# STM32L100C6U6 register map
File version: 1.0
Registers are 32-bit, access not given, reset 0x0 unless marked. A register's access mark holds for its fields unless they carry their own. Offsets are from the block's base; [hi:lo] are bit positions; {n}, {i} and the like mark numbered series.

## SYSCFG
Base 0x40010000
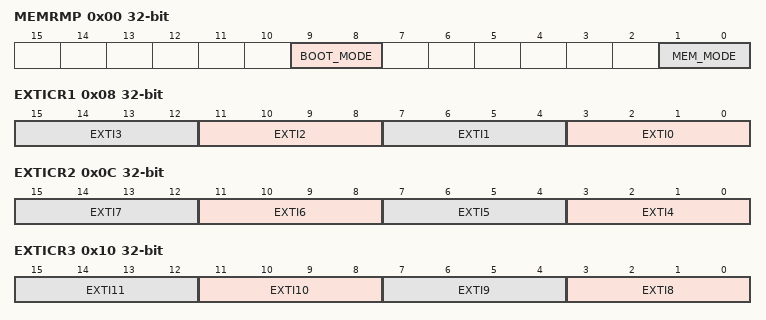
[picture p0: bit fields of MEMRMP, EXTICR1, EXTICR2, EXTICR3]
0x00 MEMRMP
  [9:8] BOOT_MODE, [1:0] MEM_MODE
0x04 PMC
  [0] USBPU
0x08 EXTICR1
  [4n+3:4n] EXTI{n} (n=0..3)
0x0C EXTICR2
  [4n-13:4n-16] EXTI{n} (n=4..7)
0x10 EXTICR3
  [4n-29:4n-32] EXTI{n} (n=8..11)
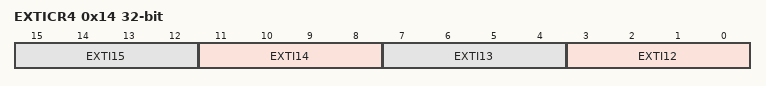
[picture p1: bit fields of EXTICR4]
0x14 EXTICR4
  [4n-45:4n-48] EXTI{n} (n=12..15)

## EXTI
Base 0x40010400
0x00 IMR
  [23:0] MR
0x04 EMR
  [23:0] MR
0x08 RTSR
  [23:0] TR
0x0C FTSR
  [23:0] TR
0x10 SWIER
  [23:0] SWIER
0x14 PR
  [23:0] PR

## TIM9
Base 0x40010800
0x00 CR1
0x04 CR2
0x08 SMCR
  [7] 0MSM
0x0C DIER
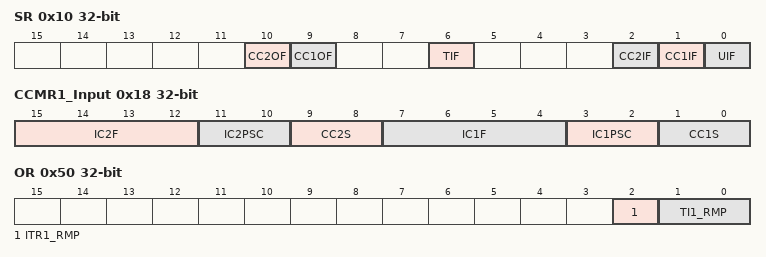
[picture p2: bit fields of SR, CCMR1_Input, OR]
0x10 SR
  [10] CC2OF, [9] CC1OF, [6] TIF, [2] CC2IF, [1] CC1IF, [0] UIF
0x14 EGR
0x18 CCMR1_Output
0x18 CCMR1_Input
  [15:12] IC2F, [11:10] IC2PSC, [9:8] CC2S, [7:4] IC1F, [3:2] IC1PSC, [1:0] CC1S
0x20 CCER
0x24 CNT
0x28 PSC
0x2C ARR
0x34 CCR1
0x38 CCR2
0x50 OR
  [2] ITR1_RMP, [1:0] TI1_RMP

## TIM10
Base 0x40010C00
Same registers: TIM11 0x40011000
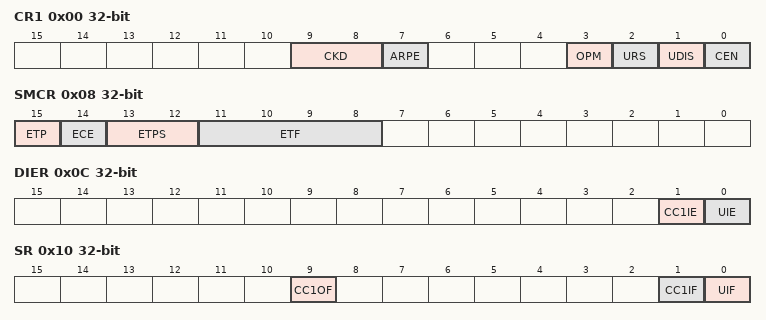
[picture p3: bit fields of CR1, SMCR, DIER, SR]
0x00 CR1
  [9:8] CKD, [7] ARPE, [3] OPM, [2] URS, [1] UDIS, [0] CEN
0x08 SMCR
  [15] ETP, [14] ECE, [13:12] ETPS, [11:8] ETF
0x0C DIER
  [1] CC1IE, [0] UIE
0x10 SR
  [9] CC1OF, [1] CC1IF, [0] UIF
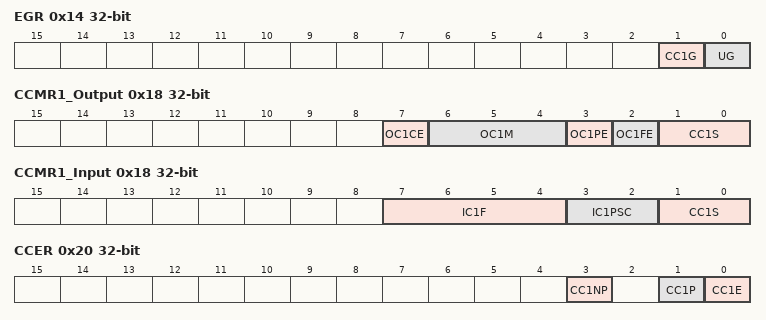
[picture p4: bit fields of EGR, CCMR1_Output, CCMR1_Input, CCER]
0x14 EGR
  [1] CC1G, [0] UG
0x18 CCMR1_Output
  [7] OC1CE, [6:4] OC1M, [3] OC1PE, [2] OC1FE, [1:0] CC1S
0x18 CCMR1_Input
  [7:4] IC1F, [3:2] IC1PSC, [1:0] CC1S
0x20 CCER
  [3] CC1NP, [1] CC1P, [0] CC1E
0x24 CNT
  [15:0] CNT
0x28 PSC
  [15:0] PSC
0x2C ARR
  [15:0] ARR
0x34 CCR1
  [15:0] CCR1
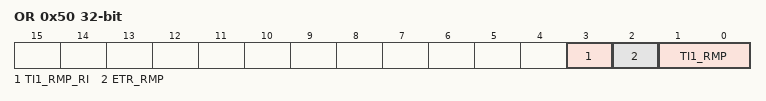
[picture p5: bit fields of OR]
0x50 OR
  [3] TI1_RMP_RI, [2] ETR_RMP, [1:0] TI1_RMP

## ADC
Base 0x40012400
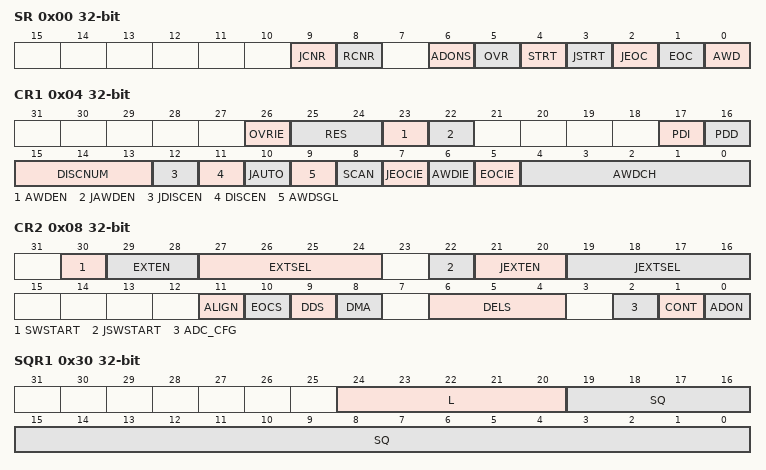
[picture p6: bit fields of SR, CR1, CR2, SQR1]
0x00 SR
  [9] JCNR, [8] RCNR, [6] ADONS, [5] OVR, [4] STRT, [3] JSTRT, [2] JEOC, [1] EOC, [0] AWD
0x04 CR1
  [26] OVRIE, [25:24] RES, [23] AWDEN, [22] JAWDEN, [17] PDI, [16] PDD, [15:13] DISCNUM, [12] JDISCEN, [11] DISCEN, [10] JAUTO, [9] AWDSGL, [8] SCAN, [7] JEOCIE, [6] AWDIE, [5] EOCIE, [4:0] AWDCH
0x08 CR2
  [30] SWSTART, [29:28] EXTEN, [27:24] EXTSEL, [22] JSWSTART, [21:20] JEXTEN, [19:16] JEXTSEL, [11] ALIGN, [10] EOCS, [9] DDS, [8] DMA, [6:4] DELS, [2] ADC_CFG, [1] CONT, [0] ADON
{0x8+4i} SMPR{i} (i=1..3)
  [31:0] SMP
{0x14+4i} JOFR{i} (i=1..4)
  [11:0] JOFFSET{i}
0x28 HTR
  [11:0] HT
0x2C LTR
  [11:0] LT
0x30 SQR1
  [24:20] L, [19:0] SQ
{0x2C+4i} SQR{i} (i=2..5)
  [29:0] SQ
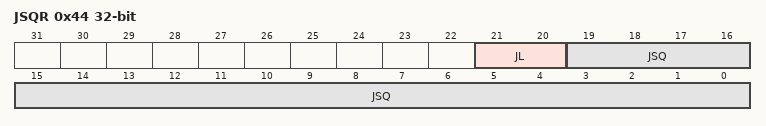
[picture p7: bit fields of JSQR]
0x44 JSQR
  [21:20] JL, [19:0] JSQ
{0x44+4i} JDR{i} (i=1..4)
  [15:0] JDATA
0x58 DR
  [15:0] DATA
0x5C SMPR0
  [31:0] SMP

## SDIO
Base 0x40012C00
0x00 POWER
  [1:0] PWRCTRL
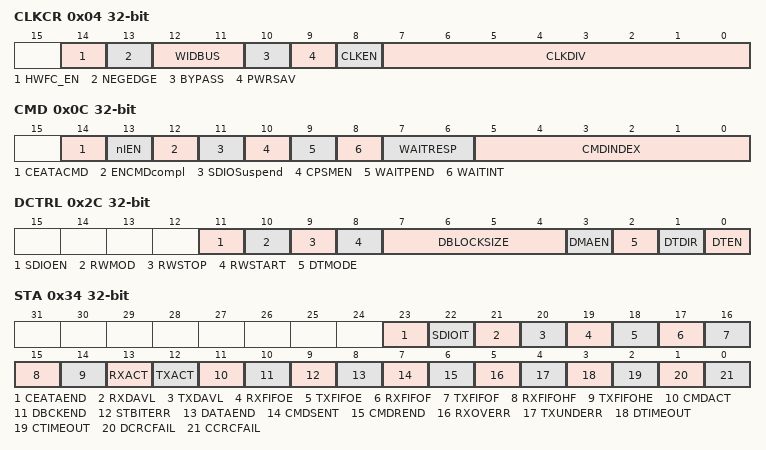
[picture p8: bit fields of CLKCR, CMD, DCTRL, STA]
0x04 CLKCR
  [14] HWFC_EN, [13] NEGEDGE, [12:11] WIDBUS, [10] BYPASS, [9] PWRSAV, [8] CLKEN, [7:0] CLKDIV
0x08 ARG
  [31:0] CMDARG
0x0C CMD
  [14] CEATACMD, [13] nIEN, [12] ENCMDcompl, [11] SDIOSuspend, [10] CPSMEN, [9] WAITPEND, [8] WAITINT, [7:6] WAITRESP, [5:0] CMDINDEX
0x10 RESPCMD
  [5:0] RESPCMD
{0x10+4i} RESP{i} (i=1..4)
  [31:0] CARDSTATUS{i}
0x24 DTIMER
  [31:0] DATATIME
0x28 DLEN
  [24:0] DATALENGTH
0x2C DCTRL
  [11] SDIOEN, [10] RWMOD, [9] RWSTOP, [8] RWSTART, [7:4] DBLOCKSIZE, [3] DMAEN, [2] DTMODE, [1] DTDIR, [0] DTEN
0x30 DCOUNT
  [24:0] DATACOUNT
0x34 STA
  [23] CEATAEND, [22] SDIOIT, [21] RXDAVL, [20] TXDAVL, [19] RXFIFOE, [18] TXFIFOE, [17] RXFIFOF, [16] TXFIFOF, [15] RXFIFOHF, [14] TXFIFOHE, [13] RXACT, [12] TXACT, [11] CMDACT, [10] DBCKEND, [9] STBITERR, [8] DATAEND, [7] CMDSENT, [6] CMDREND, [5] RXOVERR, [4] TXUNDERR, [3] DTIMEOUT, [2] CTIMEOUT, [1] DCRCFAIL, [0] CCRCFAIL
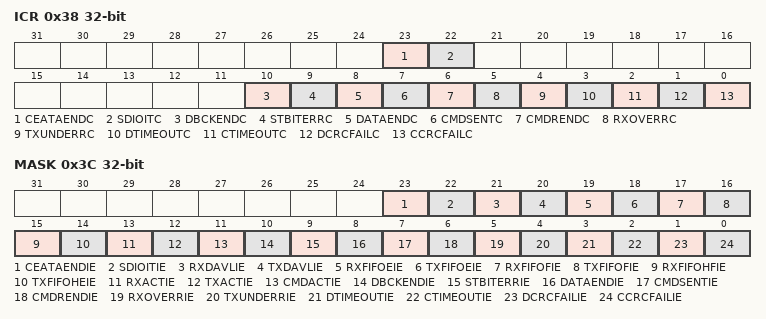
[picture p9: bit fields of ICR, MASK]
0x38 ICR
  [23] CEATAENDC, [22] SDIOITC, [10] DBCKENDC, [9] STBITERRC, [8] DATAENDC, [7] CMDSENTC, [6] CMDRENDC, [5] RXOVERRC, [4] TXUNDERRC, [3] DTIMEOUTC, [2] CTIMEOUTC, [1] DCRCFAILC, [0] CCRCFAILC
0x3C MASK
  [23] CEATAENDIE, [22] SDIOITIE, [21] RXDAVLIE, [20] TXDAVLIE, [19] RXFIFOEIE, [18] TXFIFOEIE, [17] RXFIFOFIE, [16] TXFIFOFIE, [15] RXFIFOHFIE, [14] TXFIFOHEIE, [13] RXACTIE, [12] TXACTIE, [11] CMDACTIE, [10] DBCKENDIE, [9] STBITERRIE, [8] DATAENDIE, [7] CMDSENTIE, [6] CMDRENDIE, [5] RXOVERRIE, [4] TXUNDERRIE, [3] DTIMEOUTIE, [2] CTIMEOUTIE, [1] DCRCFAILIE, [0] CCRCFAILIE
0x48 FIFOCNT
  [23:0] FIFOCOUNT
0x80 FIFO
  [31:0] FIF0Data
